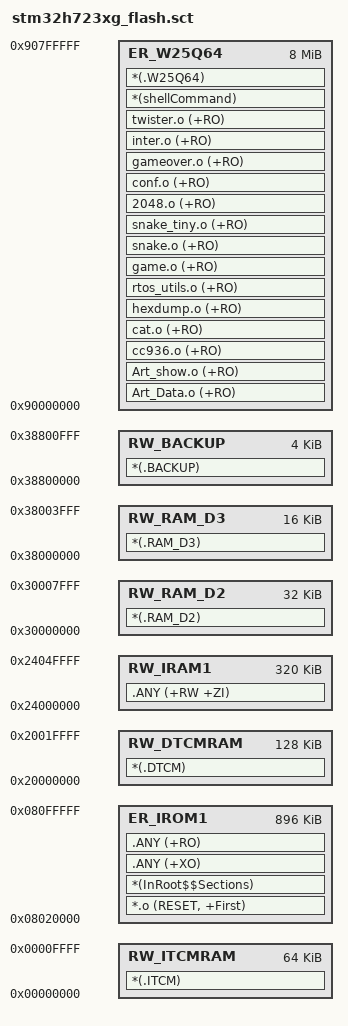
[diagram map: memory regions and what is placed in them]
; 加载区 起始地址 大小
LR_IROM1 0x08020000 0x000E0000  {
  ; 加载地址 = 执行地址
  ER_IROM1 0x08020000 0x000E0000  {
   *.o (RESET, +First)
   *(InRoot$$Sections)
   .ANY (+XO)
   .ANY (+RO)
  }

  ; 内部RAM区 起始地址 大小
  RW_IRAM1 0x24000000 0x00050000  {
   .ANY (+RW +ZI)
  }

  ; DTCM RAM区 起始地址 大小
  RW_DTCMRAM 0x20000000 0x00020000  {
    *(.DTCM)
  }

  ; RAM_D2区 起始地址 大小
  RW_RAM_D2 0x30000000 0x00008000  {
    *(.RAM_D2)
  }

  ; RAM_D3区 起始地址 大小
  RW_RAM_D3 0x38000000 0x00004000  {
    *(.RAM_D3)
  }

  ; ITCM RAM区 起始地址 大小
  RW_ITCMRAM 0x00000000 0x00010000  {
    *(.ITCM)
  }

  ; BACKUP ARM区 起始地址 大小
  RW_BACKUP 0x38800000 0x00001000  {
    *(.BACKUP)
  }
}

; 外部W25Q64 Flash区 起始地址 大小
LR_W25Q64 0x90000000 0x00800000 {
    ER_W25Q64 0x90000000 0x00800000 {
        Art_Data.o (+RO)      ; 图片数据
        Art_show.o (+RO)      ; 图片显示函数

        cc936.o (+RO)         ; CC936模块驱动

        cat.o (+RO)           ; cat命令
        hexdump.o (+RO)       ; hexdump命令

        rtos_utils.o (+RO)    ; RTOS工具集

        game.o (+RO)         	; game shell命令组入口
        snake.o (+RO)        	; 贪吃蛇
        snake_tiny.o (+RO)   	; 精简版贪吃蛇
        2048.o (+RO)         	; 2048游戏
        conf.o (+RO)         	; 配置数据
        gameover.o (+RO)     	; 结束界面
        inter.o (+RO)        	; 界面元素
        twister.o (+RO)      	; 旋转特效

        *(shellCommand)
        *(.W25Q64)
    }
}
